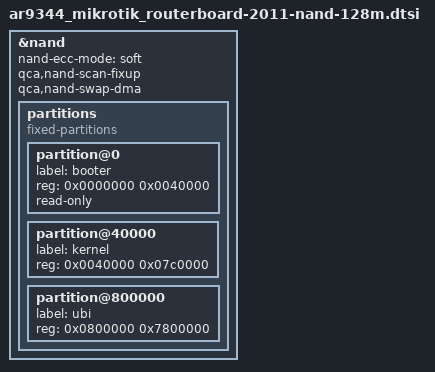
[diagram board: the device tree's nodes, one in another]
// SPDX-License-Identifier: GPL-2.0-or-later OR MIT

&nand {
	nand-ecc-mode = "soft";
	qca,nand-scan-fixup;
	qca,nand-swap-dma;
	status = "okay";

	partitions {
		compatible = "fixed-partitions";
		#address-cells = <1>;
		#size-cells = <1>;

		partition@0 {
			label = "booter";
			reg = <0x0000000 0x0040000>;
			read-only;
		};

		partition@40000 {
			label = "kernel";
			reg = <0x0040000 0x07c0000>;
		};

		partition@800000 {
			label = "ubi";
			reg = <0x0800000 0x7800000>;
		};
	};
};
